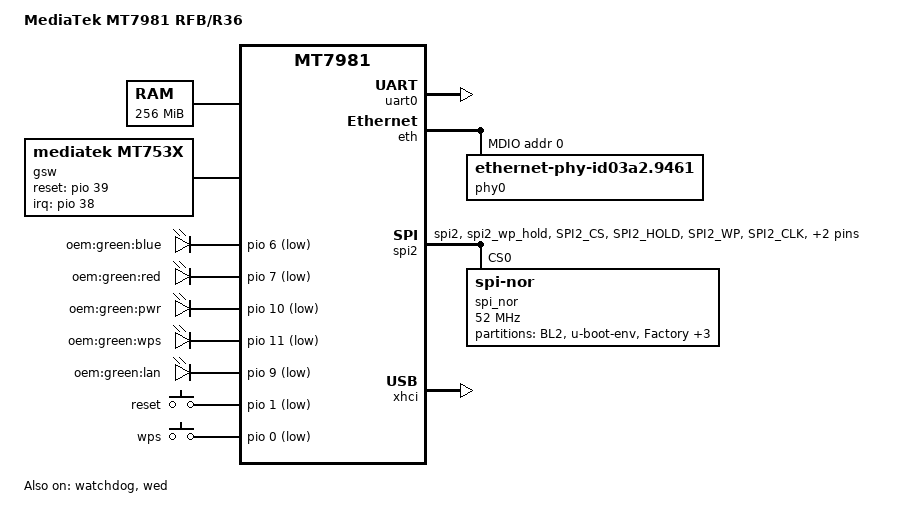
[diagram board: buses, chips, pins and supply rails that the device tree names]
/dts-v1/;
#include "mt7981.dtsi"
/ {
	model = "MediaTek MT7981 RFB/R36";
	compatible = "mediatek,mt7981-spim-nor-rfb";
	chosen {
		bootargs = "console=ttyS0,115200n1 loglevel=8  \
				earlycon=uart8250,mmio32,0x11002000";
	};

	memory {
		// fpga ddr2: 128MB*2
		reg = <0 0x40000000 0 0x10000000>;
	};

        gsw: gsw@0 {
                compatible = "mediatek,mt753x";
                mediatek,ethsys = <&ethsys>;
                #address-cells = <1>;
                #size-cells = <0>;
        };

	gpio-leds {
		compatible = "gpio-leds";
		
		blue {
			label = "oem:green:blue";
			gpios = <&pio 6 GPIO_ACTIVE_LOW>;
		};

		red {
			label = "oem:green:red";
			gpios = <&pio 7 GPIO_ACTIVE_LOW>;
		};

		pwr {
			label = "oem:green:pwr";
			gpios = <&pio 10 GPIO_ACTIVE_LOW>;
		};

		wps {
			label = "oem:green:wps";
			gpios = <&pio 11 GPIO_ACTIVE_LOW>;
		};

		lan {
			label = "oem:green:lan";
			gpios = <&pio 9 GPIO_ACTIVE_LOW>;
		};
	};

	gpio-keys-polled {
		compatible = "gpio-keys-polled";
		#address-cells = <1>;
		#size-cells = <0>;
		poll-interval = <20>;

		reset {
			label = "reset";
			gpios = <&pio 1 GPIO_ACTIVE_LOW>;
			linux,code = <KEY_RESTART>;
		};

		wps {
			label = "wps";
			gpios = <&pio 0 GPIO_ACTIVE_LOW>;
			linux,code = <KEY_WPS_BUTTON>;
		};
	};
};

&uart0 {
	status = "okay";
};

&watchdog {
	status = "okay";
};

&eth {
        status = "okay";

		gmac1: mac@1 {
			compatible = "mediatek,eth-mac";
			reg = <1>;
			mtd-mac-address = <&bdinfo 0xDE00>;
			phy-mode = "gmii";
			phy-handle = <&phy0>;
		};

        mdio: mdio-bus {
			#address-cells = <1>;
			#size-cells = <0>;

			phy0: ethernet-phy@0 {
				compatible = "ethernet-phy-id03a2.9461";
				reg = <0>;
				phy-mode = "gmii";
				nvmem-cells = <&phy_calibration>;
				nvmem-cell-names = "phy-cal-data";
			};
		};
};

&gsw {
        mediatek,mdio = <&mdio>;
        mediatek,portmap = "lllll";
        mediatek,mdio_master_pinmux = <1>;
        reset-gpios = <&pio 39 0>;
        interrupt-parent = <&pio>;
        interrupts = <38 IRQ_TYPE_LEVEL_HIGH>;
        status = "okay";

        port6: port@6 {
                compatible = "mediatek,mt753x-port";
                reg = <6>;
                phy-mode = "sgmii";
                fixed-link {
                        speed = <2500>;
                        full-duplex;
                };
        };
};

&hnat {
	mtketh-wan = "eth0.6";
	mtketh-lan = "eth0";
	mtketh-max-gmac = <2>;
	status = "disabled";
};

&spi1 {
	pinctrl-names = "default";
	pinctrl-0 = <&spic_pins>;
	status = "disabled";
};

&spi2 {
	pinctrl-names = "default";
	pinctrl-0 = <&spi2_flash_pins>;
	status = "okay";
	spi_nor@0 {
		#address-cells = <1>;
		#size-cells = <1>;
		compatible = "jedec,spi-nor";
		spi-cal-enable;
		spi-cal-mode = "read-data";
		spi-cal-datalen = <7>;
		spi-cal-data = /bits/ 8 <
			0x53 0x46 0x5F 0x42 0x4F 0x4F 0x54>; /* SF_BOOT */
		spi-cal-addrlen = <1>;
		spi-cal-addr = /bits/ 32 <0x0>;
		reg = <0>;
		spi-max-frequency = <52000000>;
		spi-tx-buswidth = <4>;
		spi-rx-buswidth = <4>;

		partition@00000 {
			label = "BL2";
			reg = <0x00000 0x0040000>;
		};
		partition@40000 {
			label = "u-boot-env";
			reg = <0x40000 0x0010000>;
		};
		partition@50000 {
			label = "Factory";
			reg = <0x50000 0x0010000>;
		};
		bdinfo: partition@60000 {
			label = "bdinfo";
			reg = <0x60000 0x0010000>;
		};
		partition@70000 {
			label = "FIP";
			reg = <0x70000 0x0080000>;
		};
		partition@F0000 {
			label = "firmware";
			reg = <0xF0000 0xF10000>;
		};
	};
};

&pio {
	spic_pins: spi1-pins {
		mux {
			function = "spi";
			groups = "spi1_1";
		};
	};

	spi2_flash_pins: spi2-pins {
		mux {
			function = "spi";
			groups = "spi2", "spi2_wp_hold";
		};

		conf-pu {
			pins = "SPI2_CS", "SPI2_HOLD", "SPI2_WP";
			drive-strength = <MTK_DRIVE_8mA>;
			bias-pull-up = <MTK_PUPD_SET_R1R0_11>;
		};

		conf-pd {
			pins = "SPI2_CLK", "SPI2_MOSI", "SPI2_MISO";
			drive-strength = <MTK_DRIVE_8mA>;
			bias-pull-down = <MTK_PUPD_SET_R1R0_11>;
		};
	};
};

&xhci {  
        status = "okay";
};

&wed {
	dy_txbm_enable = "true";
	dy_txbm_budget = <8>;
	txbm_init_sz = <8>;
	txbm_max_sz = <32>;
	status = "okay";
};
